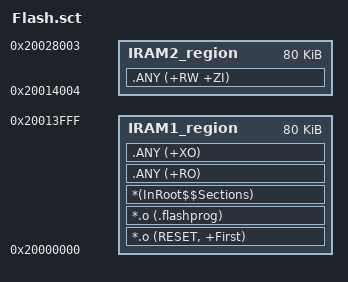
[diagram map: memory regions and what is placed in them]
#! armcc -E


; *************************************************************
; *** Scatter-Loading Description File generated by uVision ***
; *************************************************************


; ###ICF### Section handled by ICF editor, don't touch! ****/
; -Editor annotation file-*/
; /* IcfEditorFile="$TOOLKIT_DIR$\config\ide\IcfEditor\cortex_v1_1.xml" */
; /*-Specials-*/
;#define intvec_start__ 0x20000000

; /*-Memory Regions-*/
#define ROM_start      0x00000000
#define ROM_size       0x00020000
#define FLASH_start__  0x10000000
#define FLASH_size__   0x0005FFFF
#define SPIX_start__   0x08000000
#define SPIX_size__    0x05A12000
#define IRAM1_start__  0x20000000
#define IRAM1_size__   0x00014000
#define IRAM2_start__  0x20014004
#define IRAM2_size__   0x00014000
#define IRAM_size__    0x00028000

; /*-Sizes */
;#define size_cstack__  0x6000
;#define size_heap__    0x2000
; /**** End of ICF editor section. ###ICF###*/

#define memory mem with size = 4G;

;#define block CSTACK    with alignment = 8, size = size_cstack__   { };
;#define block HEAP      with alignment = 8, size = size_heap__     { };

;#define block TESTDATA { section ".testdata_space" };

;#define block FLASHINRAM { section ".flashprog" };

LR_IROM1 IRAM1_start__ IRAM_size__  {    ; load region size_region
;  FLASH_region FLASH_start__ FLASH_size__  {  ; load address = execution address
  ; *.o (RESET, +First)
  ; *(InRoot$$Sections)
  ; .ANY (+RO)
  ; .ANY (+XO)
;  }

;  SPIX_region SPIX_start__  SPIX_size__ {
;  *.o (.application_specific_ro)
;  }

  IRAM1_region IRAM1_start__  IRAM1_size__ {
   *.o (RESET, +First)  
   *.o (.flashprog)
   *(InRoot$$Sections)
   .ANY (+RO)
   .ANY (+XO)
;   .ANY (+RW +ZI)
  }
  IRAM2_region IRAM2_start__  IRAM2_size__ {
   .ANY (+RW +ZI)  
  }
  
}
